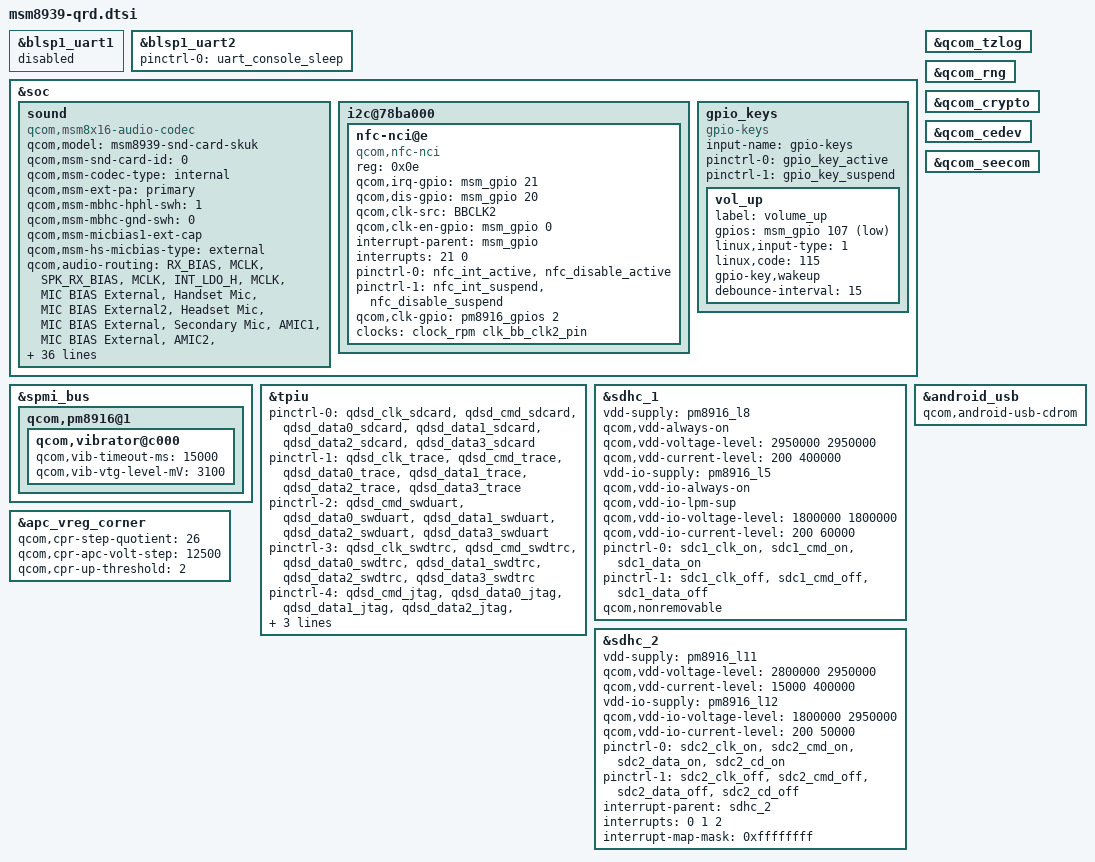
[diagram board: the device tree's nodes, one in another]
/* Copyright (c) 2014, The Linux Foundation. All rights reserved.
 *
 * This program is free software; you can redistribute it and/or modify
 * it under the terms of the GNU General Public License version 2 and
 * only version 2 as published by the Free Software Foundation.
 *
 * This program is distributed in the hope that it will be useful,
 * but WITHOUT ANY WARRANTY; without even the implied warranty of
 * MERCHANTABILITY or FITNESS FOR A PARTICULAR PURPOSE.  See the
 * GNU General Public License for more details.
 */

#include "msm8939-pinctrl.dtsi"

&blsp1_uart1 {
	status = "disabled";
};

&blsp1_uart2 {
	status = "ok";
	pinctrl-names = "default";
	pinctrl-0 = <&uart_console_sleep>;
};

&soc {
	/*delete i2c configuration of maxim charger module from here*/

	sound {
		compatible = "qcom,msm8x16-audio-codec";
		qcom,model = "msm8939-snd-card-skuk";
		qcom,msm-snd-card-id = <0>;
		qcom,msm-codec-type = "internal";
		qcom,msm-ext-pa = "primary";
		qcom,msm-mbhc-hphl-swh = <1>;
		qcom,msm-mbhc-gnd-swh = <0>;
		qcom,msm-micbias1-ext-cap;
		qcom,msm-hs-micbias-type = "external";
		qcom,audio-routing =
			"RX_BIAS", "MCLK",
			"SPK_RX_BIAS", "MCLK",
			"INT_LDO_H", "MCLK",
			"MIC BIAS External", "Handset Mic",
			"MIC BIAS External2", "Headset Mic",
			"MIC BIAS External", "Secondary Mic",
			"AMIC1", "MIC BIAS External",
			"AMIC2", "MIC BIAS External2",
			"AMIC3", "MIC BIAS External";
		pinctrl-names = "cdc_lines_act",
				"cdc_lines_sus";
		pinctrl-0 = <&cdc_pdm_lines_act>;
		pinctrl-1 = <&cdc_pdm_lines_sus>;
		asoc-platform = <&pcm0>, <&pcm1>, <&voip>, <&voice>,
				<&loopback>, <&compress>, <&hostless>,
				<&afe>, <&lsm>, <&routing>, <&lpa>;
		asoc-platform-names = "msm-pcm-dsp.0", "msm-pcm-dsp.1",
				"msm-voip-dsp", "msm-pcm-voice", "msm-pcm-loopback",
				"msm-compress-dsp", "msm-pcm-hostless", "msm-pcm-afe",
				"msm-lsm-client", "msm-pcm-routing", "msm-pcm-lpa";
		asoc-cpu = <&dai_hdmi>, <&dai_mi2s0>, <&dai_mi2s1>,
				<&dai_mi2s2>, <&dai_mi2s3>, <&sb_0_rx>, <&sb_0_tx>,
				<&sb_1_rx>, <&sb_1_tx>, <&sb_3_rx>, <&sb_3_tx>,
				<&sb_4_rx>, <&sb_4_tx>, <&sb_5_tx>, <&bt_sco_rx>,
				<&bt_sco_tx>, <&int_fm_rx>, <&int_fm_tx>, <&afe_pcm_rx>,
				<&afe_pcm_tx>, <&afe_proxy_rx>, <&afe_proxy_tx>,
				<&incall_record_rx>, <&incall_record_tx>, <&incall_music_rx>,
				<&incall_music_2_rx>;
		asoc-cpu-names = "msm-dai-q6-hdmi.8", "msm-dai-q6-mi2s.0",
				"msm-dai-q6-mi2s.1", "msm-dai-q6-mi2s.2",
				"msm-dai-q6-mi2s.3", "msm-dai-q6-dev.16384",
				"msm-dai-q6-dev.16385", "msm-dai-q6-dev.16386",
				"msm-dai-q6-dev.16387", "msm-dai-q6-dev.16390",
				"msm-dai-q6-dev.16391", "msm-dai-q6-dev.16392",
				"msm-dai-q6-dev.16393", "msm-dai-q6-dev.16395",
				"msm-dai-q6-dev.12288", "msm-dai-q6-dev.12289",
				"msm-dai-q6-dev.12292", "msm-dai-q6-dev.12293",
				"msm-dai-q6-dev.224", "msm-dai-q6-dev.225",
				"msm-dai-q6-dev.241", "msm-dai-q6-dev.240",
				"msm-dai-q6-dev.32771", "msm-dai-q6-dev.32772",
				"msm-dai-q6-dev.32773", "msm-dai-q6-dev.32770";
		asoc-codec = <&stub_codec>, <&pm8916_tombak_dig>;
		asoc-codec-names = "msm-stub-codec.1", "tombak_codec";
	};

	i2c@78ba000 { /* BLSP1 QUP6 */
		nfc-nci@e {
			compatible = "qcom,nfc-nci";
			reg = <0x0e>;
			qcom,irq-gpio = <&msm_gpio 21 0x00>;
			qcom,dis-gpio = <&msm_gpio 20 0x00>;
			qcom,clk-src = "BBCLK2";
			qcom,clk-en-gpio = <&msm_gpio 0 0x00>;
			interrupt-parent = <&msm_gpio>;
			interrupts = <21 0>;
			interrupt-names = "nfc_irq";
			pinctrl-names = "nfc_active","nfc_suspend";
			pinctrl-0 = <&nfc_int_active &nfc_disable_active>;
			pinctrl-1 = <&nfc_int_suspend &nfc_disable_suspend>;
			qcom,clk-gpio = <&pm8916_gpios 2 0>;
			clocks = <&clock_rpm clk_bb_clk2_pin>;
			clock-names = "ref_clk";
		};
	};
};

&spmi_bus {
	qcom,pm8916@1 {
		qcom,vibrator@c000 {
			status = "okay";
			qcom,vib-timeout-ms = <15000>;
			qcom,vib-vtg-level-mV = <3100>;
		};
	};
	/*
	qcom,pm8916@0 {
		qcom,leds@a100 {
			status = "okay";
			qcom,led_mpp_2 {
				label = "mpp";
				linux,name = "button-backlight";
				linux,default-trigger = "none";
				qcom,default-state = "off";
				qcom,max-current = <40>;
				qcom,current-setting = <5>;
				qcom,id = <6>;
				qcom,mode = "manual";
				qcom,source-sel = <1>;
				qcom,mode-ctrl = <0x60>;
			};
		};
	};
	*/
};

/* CoreSight */
&tpiu {
	pinctrl-names = "sdcard", "trace", "swduart",
			"swdtrc", "jtag", "spmi";
	/* NIDnT */
	pinctrl-0 = <&qdsd_clk_sdcard &qdsd_cmd_sdcard
		     &qdsd_data0_sdcard &qdsd_data1_sdcard
		     &qdsd_data2_sdcard &qdsd_data3_sdcard>;
	pinctrl-1 = <&qdsd_clk_trace &qdsd_cmd_trace
		     &qdsd_data0_trace &qdsd_data1_trace
		     &qdsd_data2_trace &qdsd_data3_trace>;
	pinctrl-2 = <&qdsd_cmd_swduart &qdsd_data0_swduart
		     &qdsd_data1_swduart &qdsd_data2_swduart
		     &qdsd_data3_swduart>;
	pinctrl-3 = <&qdsd_clk_swdtrc &qdsd_cmd_swdtrc
		     &qdsd_data0_swdtrc &qdsd_data1_swdtrc
		     &qdsd_data2_swdtrc &qdsd_data3_swdtrc>;
	pinctrl-4 = <&qdsd_cmd_jtag &qdsd_data0_jtag
		     &qdsd_data1_jtag &qdsd_data2_jtag
		     &qdsd_data3_jtag>;
	pinctrl-5 = <&qdsd_clk_spmi &qdsd_cmd_spmi
		     &qdsd_data0_spmi &qdsd_data3_spmi>;
};

&soc {
	gpio_keys {
		compatible = "gpio-keys";
		input-name = "gpio-keys";
		pinctrl-names = "tlmm_gpio_key_active","tlmm_gpio_key_suspend";
		pinctrl-0 = <&gpio_key_active>;
		pinctrl-1 = <&gpio_key_suspend>;

		vol_up {
			label = "volume_up";
			gpios = <&msm_gpio 107 0x1>;
			linux,input-type = <1>;
			linux,code = <115>;
			gpio-key,wakeup;
			debounce-interval = <15>;
		};
	};
};

&sdhc_1 {
	vdd-supply = <&pm8916_l8>;
	qcom,vdd-always-on;
	qcom,vdd-voltage-level = <2950000 2950000>;
	qcom,vdd-current-level = <200 400000>;

	vdd-io-supply = <&pm8916_l5>;
	qcom,vdd-io-always-on;
	qcom,vdd-io-lpm-sup;
	qcom,vdd-io-voltage-level = <1800000 1800000>;
	qcom,vdd-io-current-level = <200 60000>;

	pinctrl-names = "active", "sleep";
	pinctrl-0 = <&sdc1_clk_on &sdc1_cmd_on &sdc1_data_on>;
	pinctrl-1 = <&sdc1_clk_off &sdc1_cmd_off &sdc1_data_off>;

	qcom,nonremovable;

	status = "ok";
};

&sdhc_2 {
	vdd-supply = <&pm8916_l11>;
	qcom,vdd-voltage-level = <2800000 2950000>;
	qcom,vdd-current-level = <15000 400000>;

	vdd-io-supply = <&pm8916_l12>;
	qcom,vdd-io-voltage-level = <1800000 2950000>;
	qcom,vdd-io-current-level = <200 50000>;

	pinctrl-names = "active", "sleep";
	pinctrl-0 = <&sdc2_clk_on &sdc2_cmd_on &sdc2_data_on &sdc2_cd_on>;
	pinctrl-1 = <&sdc2_clk_off &sdc2_cmd_off &sdc2_data_off &sdc2_cd_off>;

	#address-cells = <0>;
	interrupt-parent = <&sdhc_2>;
	interrupts = <0 1 2>;
	#interrupt-cells = <1>;
	interrupt-map-mask = <0xffffffff>;
	interrupt-names = "hc_irq", "pwr_irq", "status_irq";

	status = "ok";
};

&qcom_tzlog {
	status = "okay";
};

&qcom_rng {
	status = "okay";
};

&qcom_crypto {
	status = "okay";
};

&qcom_cedev {
	status = "okay";
};

&qcom_seecom {
	status = "okay";
};

&android_usb {
	qcom,android-usb-cdrom;
};

&apc_vreg_corner {
	/*move this to msm8939-regulator.dtsi*/
	qcom,cpr-step-quotient = <26>;
	qcom,cpr-apc-volt-step = <12500>;
	qcom,cpr-up-threshold = <2>;
};
